# MSS_MIBSPIA register map
Vendor: Texas Instruments
Registers are 32-bit, access per field, no defined reset value unless marked. A register's access mark holds for its fields unless they carry their own. Offsets are as the file gives them; [hi:lo] are bit positions; lines under a group give offsets from that group; {n}, {i} and the like mark numbered series.

## MSS_MIBSPIA (part 3 of 4)
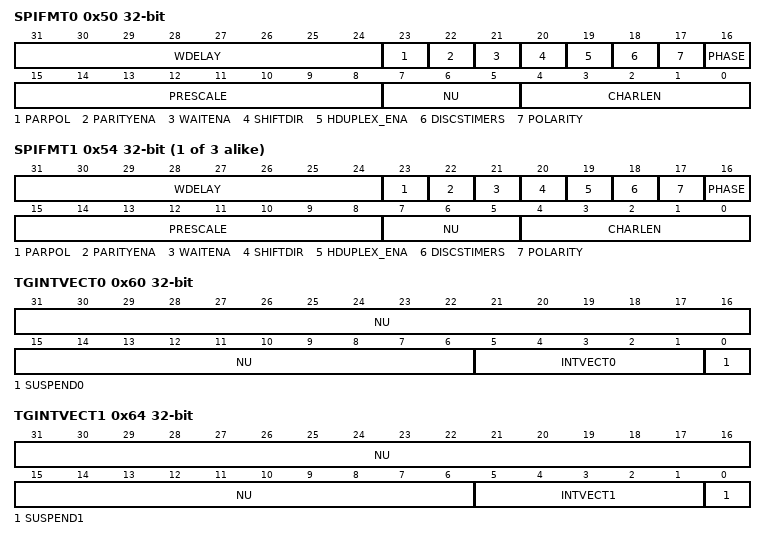
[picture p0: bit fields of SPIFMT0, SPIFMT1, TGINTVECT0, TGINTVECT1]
0x50 SPIFMT0 — SPI / MibSPI Data Format Register 0
  [31:24] WDELAY rw — Delay in between transmissions for data format x (x= 0,1,2,3). Idle time that will be applied at the end of the current transmission if the bit WDEL is set in the current buffer. The delay to be applied is equal to: WDELAY * PVBUSPCLK + 2 * PVBUSPCLK. PVBUSPCLK -> Period of VBUSPCLK.
  [23] PARPOL rw — Parity polarity: even or odd. PARPOLx can be modified in privilege mode only. It can be used for data format x (x= 0,1,2,3). 1 =An odd parity flag is added at the end of the transmit data stream. 0 =An even parity flag is added at the end of the transmit data stream.
  [22] PARITYENA rw — Parity enable for data format x. 1= A parity is transmitted at the end of each transmit data stream. At the end of a transfer the parity generator compares the received parity bit with the locally calculated parity flag. If the parity bits do not match the RXERR flag is set in the corresponding control field. The parity type (even or odd) can be selected via the PARPOL bit. 0= No parity generation/ verification is performed for this data format. If an Uncorrectable Error Flag is set in a Slave mode MibSPI, then wrong parity bit will be transmitted to indicate to the master that there has been some issue with the data parity. The SOMI pin will be forced to transmit all ‘0’s. And parity bit will be transmitted as ‘1’ if even parity is selected and as ‘0’ if odd parity is selected(using the PARPOLx bit of this register). This behavior will be irrespective of an UPE on either TXRAM or RXRAM.
  [21] WAITENA rw — Master waits for ENA signal from slave for data format x. WAITENA is considered in master mode only. In slave mode this bit has no meaning. WAITENA enables a flexible SPI network where slaves with ENA signal and slaves without ENA signal can be mixed. WAITENA defines for each buffer whether the addressed slave generates the ENA signal or does not. 1= Before the SPI / MibSPI starts the data transfer it waits for the ENA signal to become low. If the ENA signal is not pulled down by the addressed slave before the internal time-out counter (C2EDELAY) overflows, then the Master aborts the transfer and sets the TIMEOUT error flag. 0= The SPI / MibSPI does not wait for the ENA signal from the slaves and directly starts the transfer.
  [20] SHIFTDIR rw — Shift direction for data format x. With bit SHIFTDIRx the shift direction for data format x (x=0,1,2,3) can be selected. 1 =Data format x shift direction: Least significant bit is shifted out first. 0 =Data format x shift direction: Most significant bit is shifted out first.
  [19] HDUPLEX_ENA rw — Half Duplex transfer mode enable for Data Format x. This bit controls the I/O function of SOMI/SIMO lines for a specific requirement where in the case of Master mode, TX pin - SIMO will act as an RX pin, and in the case of Slave mode, RX pin - SIMO will act as a TX pin. 0 = Normal Full Duplex transfer. 1 = If MASTER = ‘1’, SIMO pin will act as an RX pin (No TX possible) If MASTER = ‘0’, SIMO pin will act as a TX pin (No RX possible). For all normal operations, HDUPLEX_ENAx bits should always remain ‘0’. It is intended for the usage when the SIMO pin is used for both TX & RX operations at different times.
  [18] DISCSTIMERS rw — Disable Chipselect Timers for this format register. The C2TDELAY & T2CDELAY timers are by default enabled for all the Data Format registers. Using this bit, these timers can be disabled for particular Data Format if not required. When a Master is handling multiple Slaves, with varied set-up hold requirement, the application can selectively choose to include or not include the ChipSelect Delay timers for any Slaves. 0 = Both C2TDELAY & T2CDELAY counts are inserted for the ChipSelects. 1 = No C2TDELAY or T2CDELAY is inserted in the ChipSelect timings.
  [17] POLARITY rw — SPI data format x clock polarity. POLARITYx defines the clock polarity of data format x. POLARITYx can be modified in privilege mode only. 1 =If POLARITYx is set to “1” the SPI clock signal is high-inactive, i.e. before and after data transfer the clock signal is high. 0 =If POLARITYx is set to “0” the SPI clock signal is low-inactive, i.e. before and after data transfer the clock signal is low.
  [16] PHASE rw — SPI Data format x clock delay. PHASEx defines the clock delay of data format x. PHASEx can be modified in privilege mode only. 1 =If PHASEx is set to “1” the SPI clock signal is delayed by a half SPI clock cycle versus the transmit / receive data stream. The first transmit bit has to output prior to the first clock edge. Master and slave receive the first bit with the first edge 0 =If PHASEx is set to “0” the SPI clock signal is not delayed versus the transmit / receive data stream. The first data bit is transmitted with the first clock edge and the first bit is received with the second (inverse) clock edge Note: Restriction on SPICLK Phase/Polarity change in Slave Mode In Slave mode if Phase and/or Polarity of SPICLK has to be changed, the following sequence should be used. oClear the GCR1.SPIEN bit to ‘0’. oSet the required Phase/Polarity values in SPIFMTx registers. oSet the GCR1.SPIEN bit back to ‘1’. The setting of GCR1.SPIEN bit in Slave SPI/MibSPI to ‘1’ should be done only after the Polarity of the incoming SPICLK signal changes (if POLARITYx bit was changed in the configuration).
  [15:8] PRESCALE rw — SPI data format x prescaler. PRESCALEx can be modified in privilege mode only. PRESCALEx determines the bit transfer rate of data format x if the SPI is the network master. PRESCALEx is directly derived from VBUSPCLK. If the SPI / MibSPI is configured as slave, PRESCALEx DOES NOT NEED to be configured. The clock rate for data format x can be calculated as BRFormat = VBUSPCLCK/(PRESCALEx+1) When PRESCALEx is set to zero (0), the SPI clock rate defaults to VBUSPCLK/2. Any write to this field will update EPRESCALE_FMTx field of EPRESCALEy (y=1,2) registers with EPRESCALE_FMTx(11:8) bits rounded off to ‘000’. Any write to EPRESCALE_FMTx field of the EXTENDED_PRESCALEy (y=1,2) register will cause its lower 8bits to be reflected in this field as well.
  [7:5] NU ro — Reserved. Reads return ‘0’ and writes have no effect.
  [4:0] CHARLEN rw — SPI data format x data word length. CHARLENx defines the word length of data format x. Legal values are 0x02 (data word length = 2 bit) to 0x10 (data word length = 16). Illegal values, such as 0x00 or 0x1F are not detected and their effect is indeterminate.
{0x50+4i} SPIFMT{i} (i=1..3) — SPI / MibSPI Data Format Register {i}
  [31:24] WDELAY rw
  [23] PARPOL rw
  [22] PARITYENA rw
  [21] WAITENA rw
  [20] SHIFTDIR rw
  [19] HDUPLEX_ENA rw
  [18] DISCSTIMERS rw
  [17] POLARITY rw
  [16] PHASE rw
  [15:8] PRESCALE rw
  [7:5] NU ro — Reserved. Reads return ‘0’ and writes have no effect.
  [4:0] CHARLEN rw
0x60 TGINTVECT0 ro — SPI Interrupt Vector Register 0 / MibSPI Transfer Group Interrupt Vector Register 0
  [31:6] NU — Reserved. Reads return ‘0’ and writes have no effect.
  [5:1] INTVECT0 — Interrupt vector for interrupt line INT0. INTVECT0 returns the vector of the pending interrupt at interrupt line INT0. If more than one interrupts are pending, INTVECT0 always references the highest priority interrupt source first. The vectors generated are different for SPI / Compatibility mode of MibSPI and Multibuffer mode of MibSPI. INTVECT0 field just reflects the status of SPIFLG register in a vectorized format. So, any updates to SPIFLG will automatically reflect in the Vector value in this register. SPI / Compatibility mode - MibSPI The interrupts available for SPI or Compatibility mode - MibSPI, in the descending order of their priorities are as given below. Transmission Error Interrupt Receive Buffer Overrun Interrupt Receive Buffer Full Interrupt Transmit Buffer Empty Interrupt Vectors for each of these interrupts will be reflected on the INTVECT0 bits, when they occur. Reading the vectors for the “Receive Buffer Overrun” & “Receive Buffer Full” interrupts will automatically clear the respective flags in the SPIFLG register. On reading the INTVECT0 bits, the vector of the next highest priority interrupt (if any) will be then reflected on the INTVECT0 bits. If two or more interrupts occur simultaneously, the vector for the higest priority interrupt will be reflected on the INTVECT0 bits. Reading the Vector register when “Transmitter Empty” is indicated does not clear the TXINTFLG in SPIFLG register. Writing a new data to SPIDATx register clears the “Transmitter Empty” interrupt. INTVECT0[4:0] Description 00000b no interrupt pending 10001b Error interrupt pending. Refer to Least Significant (LS) Byte of SPIFLG to determine more details about the type of error. 10011b Pending interrupt is “Receive Buffer Overrun Interrupt” 10010b Pending interrupt is “Receive Buffer Full Interrupt” 10100b Pending interrupt is “Transmit Buffer Empty Interrupt” All other bit combinations Reserved Note: Exception for clearing of RXINT If both SPIBUF and RXBUF (internal buffer) are full, then, reading TGINTVECT0 register (while it shows 10010) does not clear the RXINTFLG in SPIFLG register. In this case, only way to clear the Interrupt is to read the SPIBUF again until there’s no more unread RX data.
  [0] SUSPEND0 — “Transfer suspended” or “transfer finished” interrupt.(MibSPI only) The SUSPEND0 flag is updated depending on the type of interrupt reflected by the VECTOR value field. 1 =The interrupt type is a “transfer suspended” interrupt. I.e. the transfer group referenced by INTVECT0 has asserted an interrupt, because the buffer to be transferred next is in “suspend to wait” mode. 0 =The interrupt type is a “transfer finished” interrupt. I.e. the buffer array referenced by INTVECT0 has asserted an interrupt, because all of the data from the whole transfer group has been transferred. Note: Special case for SUSPEND interrupt When there’s a “transfer suspended” interrupt (SUSPEND0 bit is set to ‘1’), reading the TGINTVECT0 register does not clear the “TG Suspended” interrupt. The SUSPEND condition should be resolved first before the interrupt can be cleared. The SUSPEND condition can be cleared by writing a new data to that TXRAM location and/or reading the data from that RXRAM location depending upon the SUSPEND criteria programmed in the “BUFMODE” field of that TXRAM location. The SUSPEND0 bit always returns value ‘0’ in SPI / Compatibility mode MibSPI. When there is an RXOVRN or any Error interrupt in Multibuffer mode, SUSPEND0 bit stays ‘0’. Refer to Section 6.2 on page 77 & Section 6.3 on page 77 for more details and notes on better handling of interrupts. Note: Reading Error Vector Reading an Error Vector in the TGINTVECT0 register will NOT clear the Error flags in the SPIFLG register. The Error Flags in SPIFLG need to be write-cleared after servicing them suitably. If “TG Completed” interrupt occurs for a TG and after a while “TG Suspended” flag too gets set for the same TG, then the TGINTVECT0 register will show “TG Completed” interrupt giving it higher priority than the “TG Suspended” interrrupt.
0x64 TGINTVECT1 ro — SPI Interrupt Vector Register 1 / MibSPI Transfer Group Interrupt Vector Register 1
  [31:6] NU — Reserved. Reads return ‘0’ and writes have no effect.
  [5:1] INTVECT1 — Interrupt vector for interrupt line INT1. INTVECT1 returns the vector of the pending interrupt at interrupt line INT0. If more than one interrupt is pending, INTVECT1 always references the highest priority interrupt source first. The vectors generated are different for SPI / Compatibility mode of MibSPI and Multibuffer mode of MibSPI. INTVECT1 field just reflects the status of SPIFLG register in a vectorized format. So, any updates to SPIFLG will automatically reflect in the Vector value in this register. SPI / Compatibility mode - MibSPI The interrupts available for SPI / Compatibility mode - MibSPI, in the descending order of their priorities are as given below. Transmission Error Interrupt Receive Buffer Overrun Interrupt Receive Buffer Full Interrupt Transmit Buffer Empty Interrupt Vectors for each of these interrupts will be reflected on the INTVECT1 bits, when they occur. Reading the vectors for the “Receive Buffer Overrun” & “Receive Buffer Full” interrupts will automatically clear the respective flags in the SPIFLG register. On reading the INTVECT1 bits, the vector of the next highest priority interrupt (if any) will then be reflected on the INTVECT1 bits. If two or more interrupts occur simultaneously, the vector for the higest priority interrupt will be reflected on the INTVECT1 bits. Reading the Vector register when “Transmitter Empty” is indicated does not clear the TXINTFLG in SPIFLG register. Writing a new data to SPIDATx register clears the “Transmitter Empty” interrupt. 00000b no interrupt pending 10001b Error interrupt pending. Refer to LS Byte of SPIFLG to determine more details about the type of error. 10011b Pending interrupt is “Receive Buffer Overrun Interrupt” 10010b Pending interrupt is “Receive Buiffer Full Interrupt” 10100b Pending interrupt is “Transmit Buffer Empty Interrupt” All other bit combinations Reserved Note: Exception for clearing of RXINT If both SPIBUF and RXBUF (internal buffer) are full, then, reading TGINTVECT1 register (while it shows 10010) does not clear the RXINTFLG in SPIFLG register. In this case, only way to clear the Interrupt is to read out the SPIBUF again until there’s no more unread RX data.
  [0] SUSPEND1 — “Transfer suspended” or “transfer finished” interrupt.(MibSPI Only) The SUSPEND1 flag is updated depending on the type of interrupt reflected by the VECTOR value field. 1 =The interrupt type is a “transfer suspended” interrupt. I.e. the transfer group referenced by INTVECT1 has asserted an interrupt, because the buffer to be transferred next is in “suspend to wait” mode. 0 =The interrupt type is a “transfer finished” interrupt. I.e. the buffer array referenced by INTVECT1 has asserted an interrupt, because all data from the whole transfer group has been transferred. Note: Special case for SUSPEND interrupt When there’s a “transfer suspended” interrupt(SUSPEND1 bit is set to ‘1’), reading the TGINTVECT1 register does not clear the “TG Suspended” interrupt. The SUSPEND condition should be resolved first before the interrupt can be cleared. This condition can be cleared by writing a new data to that TXRAM location and/or reading the data from that RXRAM location depending upon the SUSPEND criteria programmed in the “BUFMODE” field of that TXRAM location. The SUSPEND1 bit always returns value ‘0’ in SPI / Compatibility mode MibSPI. Even while there is an RXOVRN or any Error interrupt in Multibuffer mode, SUSPEND1 bit stays ‘0’. Refer to Section 6.2 on page 77 & Section 6.3 on page 77 for more details and notes on better handling of interrupts. Note: Reading Error Vector Reading an Error Vector in the TGINTVECT1 register will NOT clear the Error flags in the SPIFLG register. The Error Flags in SPIFLG need to be write-cleared after servicing them suitably. If “TG Completed” interrupt occurs for a TG and after a while “TG Suspended” flag too gets set for the same TG, then the TGINTVECT1 register will show “TG Completed” interrupt giving it higher priority than the “TG Suspended” interrrupt.
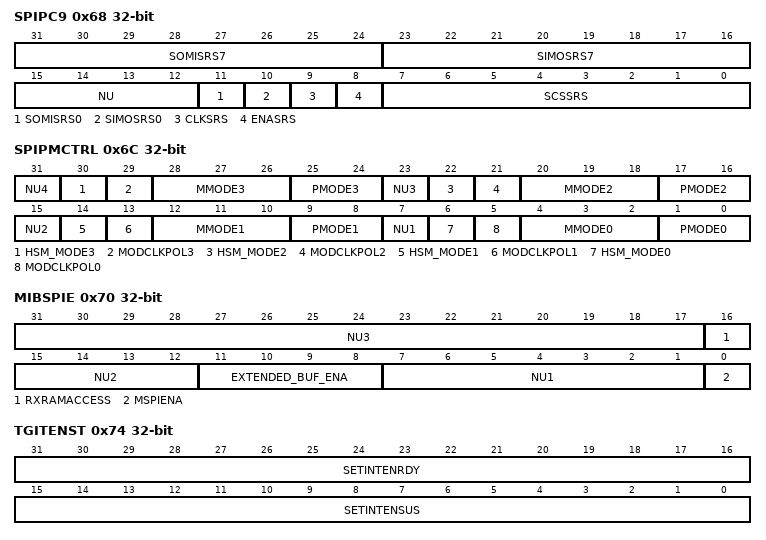
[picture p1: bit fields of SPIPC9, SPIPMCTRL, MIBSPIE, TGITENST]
0x68 SPIPC9 — SPI/MibSPI Pin Control Register 9 (SPIPC9) - SPISRSEL
  [31:24] SOMISRS7 rw — Each of these 7 bits controls the slew rate for the corresponding SPISOMIx pin. 0 =Normal Buffer Select. 1 =Slow Buffer Select.
  [23:16] SIMOSRS7 rw — Each of these 7 bits controls the slew rate for the corresponding SPISIMOx pin. 0 =Normal Buffer Select. 1 =Slow Buffer Select.
  [15:12] NU ro — Reserved. Reads return ‘0’ and writes have no effect.
  [11] SOMISRS0 rw — This bit controls the slew rate for SPISOMI0 pin. 0 =Normal Buffer Select. 1 =Slow Buffer Select. Note: Bit 11 or bit 24 can be used to control the slew rate for SPISOMI0. If a 32 bit write is performed, bit 11 will have priority over bit 24.
  [10] SIMOSRS0 rw — This bit controls the slew rate for SPISIMO0 pin. 0 =Normal Buffer Select. 1 =Slow Buffer Select. Note: Bit 10 or bit 16 can be used to control the slew rate for SPISIMO0. If a 32 bit write is performed, bit 10 will have priority over bit 16.
  [9] CLKSRS rw — This bit controls the slew rate for SPICLK pin. 0 =Normal Buffer Select. 1 =Slow Buffer Select.
  [8] ENASRS rw — This bit controls the slew rate for SPIENA pin. 0 =Fast Buffer Select. 1 =Slow Buffer Select.
  [7:0] SCSSRS rw — Each of these 7 bits controls the slew rate for the corresponding SPISCSx pin. 0 =Normal Buffer Select. 1 =Slow Buffer Select. Note: Effect of NUM_CS_PINS generic on ChipSelect bits. Actual number of bits implemented in SCSSRS[7:0] will depend upon the NUM_CS_PINS generic set during synthesis. Unimplemented bits will be read-only and will read ‘0’ always.
0x6C SPIPMCTRL — SPI/MibSPI Parallel/Modulo Mode Control Register
  [8n-1] NU{n} ro (n=1..4) — Reserved. Reads return ‘0’ and writes have no effect.
  [30] HSM_MODE3 rw — High Speed Modulo Mode control bit for Data Format 3. Controls whether the PMODE3 bits will result in Modulo Format data transfer or not. Refer to Section 3.26 for details about the HSM Mode. 0 = Normal mode - Normal Parallel mode if PMODE3 bits are non-zero. 1 = High Speed Modulo Mode. Data transfer will happen in Modulo Format if PMODE3 bits are non-zero
  [29] MODCLKPOL3 rw — Modulo mode SPICLK Polarity for Data Format 3 Determines the Polarity of the SPICLK in Modulo mode only. If MODULO MODE[2:0] bits are “000”, this bit will be ignored. 0 = Normal SPICLK in all the modes. 1 = Polarity of the SPICLK will be inverted if Modulo mode is selected
  [28:26] MMODE3 rw — These bits determine whether the SPI/MibSPI operates with 1, 2, 4, 5, or 6 data lines (if Modulo Option is supported by the module) for Data Format 3.000 = Normal single dataline mode - Default (PMODE should be set to “00”) 001 = 2-data line Mode (PMODE should be set to “00”) 010 = 3-data line mode (PMODE should be set to “00”) 011 = 4-data line mode (PMODE should be set to “00”) 100 = 5-data line mode (PMODE should be set to “00”) 101 = 6-data line mode (PMODE should be set to “01”) 110 = Reserved 111 = Reserved
  [25:24] PMODE3 rw — Parallel mode bits determine whether the SPI/MibSPI operates with 1, 2 ,4 or 8 data lines for Data Format 3. 00 = normal operation / 1-data line (MMODE should be set to “000”) 01 = 2-data line mode (MMODE should be set to “000”) 10 = 4-data line mode (MMODE should be set to “000”) 11 = 8-data line mode (MMODE should be set to “000”)
  [22] HSM_MODE2 rw — High Speed Modulo Mode control bit for Data Format 2. Controls whether the PMODE2 bits will result in Modulo Format data transfer or not. Refer to Section 3.26 for details about the HSM Mode. 0 = Normal mode - Normal Parallel mode if PMODE2 bits are non-zero. 1 = High Speed Modulo Mode. Data transfer will happen in Modulo Format if PMODE2 bits are non-zero
  [21] MODCLKPOL2 rw — Modulo mode SPICLK Polarity for Data Format 2. Determines the Polarity of the SPICLK in Modulo mode only. If MMODE[2:0] bits are “000”, this bit will be ignored. 0 = Normal SPICLK in all the modes. 1 = Polarity of the SPICLK will be inverted if Modulo mode is selected
  [20:18] MMODE2 rw — These bits determine whether the SPI/MibSPI operates with 1, 2, 4, 5, or 6 data lines (if Modulo Option is supported by the module) for Data Format 2. 000 = 1-data line Mode - Default (PMODE should be set to “00”) 001 = 2-data line Mode (PMODE should be set to “00”) 010 = 3-data line mode (PMODE should be set to “00”) 011 = 4-data line mode (PMODE should be set to “00”) 100 = 5-data line mode (PMODE should be set to “00”) 101 = 6-data line mode (PMODE should be set to “01”) 110 = Reserved 111 = Reserved
  [17:16] PMODE2 rw — Parallel mode bits determine whether the SPI/MibSPI operates with 1, 2 ,4 or 8 data lines for Data Format 2. 00 = normal operation / 1-data line (MMODE should be set to “000”) 01 = 2-data line mode (MMODE should be set to “000”)10 = 4-data line mode (MMODE should be set to “000”) 11 = 8-data line mode (MMODE should be set to “000”)
  [14] HSM_MODE1 rw — High Speed Modulo Mode control bit for Data Format 1. Controls whether the PMODE1 bits will result in Modulo Format data transfer or not. Refer to Section 3.26 for details about the HSM Mode. 0 = Normal mode - Normal Parallel mode if PMODE1 bits are non-zero. 1 = High Speed Modulo Mode. Data transfer will happen in Modulo Format if PMODE1 bits are non-zero.
  [13] MODCLKPOL1 rw — Modulo mode SPICLK Polarity for Data Format 1. Determines the Polarity of the SPICLK in Modulo mode only. If MMODE[2:0] bits are “000”, this bit will be ignored. 0 = Normal SPICLK in all the modes. 1 = Polarity of the SPICLK will be inverted if Modulo mode is selected.
  [12:10] MMODE1 rw — These bits determine whether the SPI/MibSPI operates with 1, 2, 4, 5, or 6 data lines (if Modulo Option is supported by the module) for Data Format 1. 000 = 1-data line Mode - Default (PMODE should be set to “00”) 001 = 2-data line Mode (PMODE should be set to “00”) 010 = 3-data line mode (PMODE should be set to “00”) 011 = 4-data line mode (PMODE should be set to “00”) 100 = 5-data line mode (PMODE should be set to “00”) 101 = 6-data line mode (PMODE should be set to “01”) 110 = Reserved 111 = Reserved
  [9:8] PMODE1 rw — Parallel mode bits determine whether the SPI/MibSPI operates with 1, 2 ,4 or 8 data lines for Data Format 1. 00 = normal operation / 1-data line (MMODE should be set to “000”) 01 = 2-data line mode (MMODE should be set to “000”) 10 = 4-data line mode (MMODE should be set to “000”) 11 = 8-data line mode (MMODE should be set to “000”)
  [6] HSM_MODE0 rw — High Speed Modulo Mode control bit for Data Format 0. Controls whether the PMODE0 bits will result in Modulo Format data transfer or not. Refer to Section 3.26 for details about the HSM Mode. 0 = Normal mode - Normal Parallel mode if PMODE0 bits are non-zero. 1 = High Speed Modulo Mode. Data transfer will happen in Modulo Format if PMODE0 bits are non-zero.
  [5] MODCLKPOL0 rw — Modulo mode SPICLK Polarity for Data Format 0. Determines the Polarity of the SPICLK in Modulo mode only. If MMODE[2:0] bits are “000”, this bit will be ignored. 0 = Normal SPICLK in all the modes. 1 = Polarity of the SPICLK will be inverted if Modulo mode is selected.
  [4:2] MMODE0 rw — These bits determine whether the SPI/MibSPI operates with 1, 2, 4, 5, or 6 data lines (if Modulo Option is supported by the module) for Data Format 0. 000 = 1-data line Mode - Default (PMODE should be set to “00”) 001 = 2-data line Mode (PMODE should be set to “00”) 010 = 3-data line mode (PMODE should be set to “00”) 011 = 4-data line mode (PMODE should be set to “00”) 100 = 5-data line mode (PMODE should be set to “00”) 101 = 6-data line mode (PMODE should be set to “01”) 110 = Reserved 111 = Reserved
  [1:0] PMODE0 rw — Parallel mode bits determine whether the SPI/MibSPI operates with 1, 2 ,4 or 8 data lines for Data Format 0. 00 = normal operation / 1-data line (MMODE should be set to “000”) 01 = 2-data line mode (MMODE should be set to “000”) 10 = 4-data line mode (MMODE should be set to “000”) 11 = 8-data line mode (MMODE should be set to “000”)
0x70 MIBSPIE — MibSPI Enable Register
  [31:17] NU3 ro — Reserved. Reads return ‘0’ and writes have no effect.
  [16] RXRAMACCESS rw — Receive RAM Access control Bit. During normal operating mode of MibSPI, the Receive Data/Status portion of Multibuffer RAM is read-only. To enable testing of Data Integrity checks of Receive RAM, a special read/write access control is provided through this bit. 0 = The RX portion of Multibuffer RAM is not writable by the CPU. That is, portion of Multibuffer RAM, addressed by an offset of 0x200-0x3FF is write protected. 1 = The whole of Multibuffer RAM is fully accessible for read/write by the CPU.
  [15:12] NU2 ro — Reserved.Reads return ‘0’ and writes have no effect
  [11:8] EXTENDED_BUF_ENA rw — Enables the support for 256 buffers. By default MibSPI supports up to 128 buffers for both TX and RX. It is also possible to extend the support to 256 buffers as a parameterized implementation. This field can be used to enable/disable the support for Extended Buffers. This Enable field is implemented only if “EXTENDED_BUF” parameter is set to ‘1’. If the parameter is set to ‘0’, this field is read-only and reads the disable value. Write (Privilege mode only) 1010 - Enable the Extended Buffer mode - up to 256 buffers can be used 0101 - Disable the Extended Buffer mode - MibSPI supports only 128 buffers All other values - writes are ignored and the values are not updated into this field. The state of the feature remains unchanged. Read (both privilege and user modes) 1010 - Extended Buffer mode is enabled - up to 256 buffers can be used 0101 - Extended Buffer mode is disabled - MibSPI supports only 128 buffers
  [7:1] NU1 ro — Reserved. Reads return ‘0’ and writes have no effect.
  [0] MSPIENA rw — Multibuffer mode Enable. After power-up or reset MSPIENA remains cleared, which means that the MibSPI runs in compatibility mode by default. If Multibuffer mode is desired, this register should be configured first after configuring the SPIGCR0 register. Unless MSPIENA is set to ‘1’, the Multibuffer mode registers are not writable. Refer to Section 3.3 for the grouping of registers into Compatibility mode and Multibuffer mode. 1 =The MibSPI is configured to run in MibSPI mode (Multibuffer mode). In this mode the additional features are available. 0 =The MibSPI runs in compatibility mode, i.e. in this mode the MibSPI is fully code compliant to the standard TMS470 Platform SPI. No Multibuffer feature is supported
0x74 TGITENST rw — MibSPI Transfer Group Interrupt Enable Set Register
  [31:16] SETINTENRDY — Transfer group interrupt set (enable) when transfer finished. Write: 1 = Enables the “The Transfer group x completed “ interrupt Interrupt gets generated when Transfer Group x gets completed. 0 = Has no effect. Read: 1 = “The Transfer group x completed “ interrupt is enabled Interrupt gets generated when Transfer Group x gets completed. 0 = “The Transfer group x completed” interrupt is disabled Interrupt does not get generated when Transfer Group x gets completed
  [15:0] SETINTENSUS — Transfer group interrupt set (enable) when transfer suspended Write: 1 = Enables the “The Transfer group x suspended “ interrupt Interrupt gets generated when Transfer Group x gets suspended. 0 = Has no effect. Read: 1 = “The Transfer group x suspended “ interrupt is enabled Interrupt gets generated when Transfer Group x gets suspended. 0 = “The Transfer group x suspended” interrupt is disabled Interrupt does not get generated when Transfer Group x gets suspended
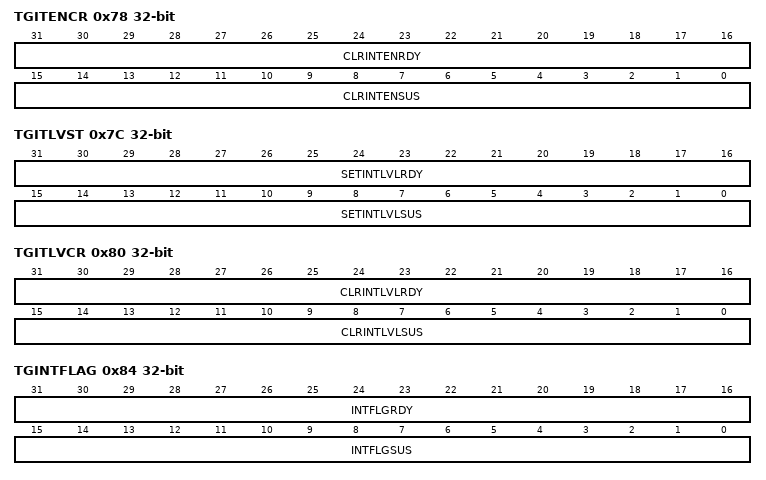
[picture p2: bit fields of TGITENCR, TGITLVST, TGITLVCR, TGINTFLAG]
0x78 TGITENCR rw — MibSPI Transfer Group Interrupt Enable Clear Register
  [31:16] CLRINTENRDY — Transfer group interrupt clear (disable) when transfer finished. Write: 1 = Disables the “The Transfer group x completed “ interrupt Interrupt does not get generated when Transfer Group x gets completed. 0 = Has no effect. Read: 1 = “The Transfer group x completed “ interrupt is enabled Interrupt gets generated when Transfer Group x gets completed. 0 = “The Transfer group x completed” interrupt is disabled Interrupt does not get generated when Transfer Group x gets completed
  [15:0] CLRINTENSUS — Transfer group interrupt clear (disable) when transfer suspended Write: 1 = Disables the “The Transfer group x suspended “ interrupt Interrupt does not get generated when Transfer Group x gets suspended. 0 = Has no effect. Read: 1 = “The Transfer group x suspended “ interrupt is enabled Interrupt gets generated when Transfer Group x gets suspended. 0 = “The Transfer group x suspended” interrupt is disabled Interrupt does not get generated when Transfer Group x gets suspended
0x7C TGITLVST rw — MibSPI Transfer Group Interrupt Level Set Register
  [31:16] SETINTLVLRDY — Transfer group completed” Interrupt Level set register Write: 1 = Sets the “The Transfer group x completed “ interrupt to line INT1 0 = Has no effect. Read: 1 = “The Transfer group x completed “ interrupt is set to line INT1 0 = “The Transfer group x completed “ interrupt is set to line INT0
  [15:0] SETINTLVLSUS — Transfer group suspended” interrupt Level set rigester Write: 1 = Sets the “The Transfer group x suspended “ interrupt to line INT1 0 = Has no effect. Read: 1 = “The Transfer group x suspended “ interrupt is set to line INT1 0 = “The Transfer group x suspended “ interrupt is set to line INT0
0x80 TGITLVCR rw — MibSPI Transfer Group Interrupt Level Clear Register
  [31:16] CLRINTLVLRDY — Transfer group completed” Interrupt Level clear register Write: 1 = Sets the “The Transfer group x completed “ interrupt to line INT0 0 = Has no effect. Read: 1 = “The Transfer group x completed “ interrupt is set to line INT1 0 = “The Transfer group x completed “ interrupt is set to line INT0
  [15:0] CLRINTLVLSUS — Transfer group suspended” interrupt Level clear register Write: 1 = Sets the “The Transfer group x suspended “ interrupt to line INT0 0 = Has no effect. Read: 1 = “The Transfer group x suspended “ interrupt is set to line INT1 0 = “The Transfer group x suspended “ interrupt is set to line INT0
0x84 TGINTFLAG ro — Transfer Group Interrupt Flag Register
  [31:16] INTFLGRDY — Transfer group interrupt flag for “transfer finished” interrupt. Read: 1 =A “transfer finished” interrupt from transfer group x occurred. No matter whether the interrupt is enabled or disabled (INTENRDYx = don’t care) or whether the interrupt is mapped to line INT0 or INT1, INTFLGRDYx is set right after the transfer from transfer group x is finished. 0 =No “transfer finished” interrupt occurred since last clearing of the flag INTFLGRDYx. Write: 1 = Clears the corresponding bit flag. 0 = Has no effect.
  [15:0] INTFLGSUS — Transfer group interrupt flag for “transfer suspend” interrupt. Read: 1 =A “transfer suspended” interrupt from transfer group x occurred. No matter whether the interrupt is enabled or disabled (INTENSUSx = don’t care) or whether the interrupt is mapped to line INT0 or INT1, INTFLGSUSx is set right after the transfer from transfer group x is suspended. 0 =No ”transfer suspended” interrupt occurred since last clearing of the flag INTFLGSUSx. Note: Read Clear Behavior Reading the interrupt vector registers TGINTVECT0 or TGINTVECT1 automatically clears the interrupt flag bit INTFLGRDYx referenced by the vector number given by INTVECT0/INTVECT1 bits, if SUSPEND0/SUPEND1 bit in the Vector registers is ‘0’.
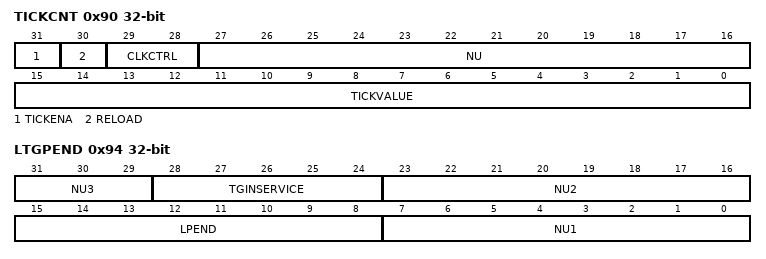
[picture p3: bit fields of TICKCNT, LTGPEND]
0x90 TICKCNT — Tick Count Register
  [31] TICKENA rw — Tick counter enable. 1 =The MibSPI internal tick counter is enabled and is clocked by the clock source selected by CLKCTRL[1:0]. When the tick counter is enabled it starts down-counting from its current value. When TICKENA goes from “0” to “1” the tick counter is automatically loaded with the TICKVALUE. 0 =The MibSPI internal tick counter is disabled. The counter value remains unchanged. Note: When the tick counter is disabled the trigger signal is forced low.
  [30] RELOAD ro — Re-load tick counter. RELOAD is a set-only bit, i.e. writing a “1” to it automatically reloads the Tick Counter with the value stored in TICKVALUE. Reading RELOAD always returns a “0”. Note: When the tick counter is reloaded by the RELOAD bit, the trigger signal is not toggled.
  [29:28] CLKCTRL rw — Tick counter clock source control. CLKCTRL[1:0] defines the clock source that is used to clock the MibSPI internal tick counter.CLKCTRL[1:0] Description 00b SPICLK of Data word format 0 is selected as clock source of tick counter 01b SPICLK of Data word format 1 is selected as clock source of tick counter 10b SPICLK of Data word format 2 is selected as clock source of tick counter 11b SPICLK of Data word format 3 is selected as clock source of tick counter
  [27:16] NU ro — Reserved.Reads return ‘0’ and writes have no effect
  [15:0] TICKVALUE rw — Initial value for tick counter. TICKVALUE stores the initial value for the tick counter. The tick counter is loaded with TICKVALUE every time an under-flow condition occurs and every time the RELOAD flag is set by the host
0x94 LTGPEND — Last Transfer Group End Pointer
  [31:29] NU3 ro — Reserved.Reads return ‘0’ and writes have no effect
  [28:24] TGINSERVICE ro — Transfer Group currently being serviced by the Sequencer. Read-Only field indicating the current Transfer Group that is being serviced. This field can generally be used for code debug purpose. Read Value:TG IN SERVICE[4:0] Description 00000b No Transfer Group is being serviced by the Sequencer 00001b Transfer Group0 is being serviced by the Sequencer ... ... 10000b Transfer Group15 is being serviced by the Sequencer 10001b - 11111b Invalid values
  [23:16] NU2 ro — Reserved.Reads return ‘0’ and writes have no effect
  [15:8] LPEND rw — Last Transfer Group End Pointer Usually the transfer group end address (PEND) is inherently defined by the start value of the starting pointer of the subsequent transfer group (PSTART). The transfer group ends at the buffer one before the next transfer group starts (PEND[x]=PSTART[x+1] - 1). For a full configuration of MibSPI, the 15th transfer group has no subsequent transfer group, i.e. no end address is inherently defined. Therefore LPEND has to be programmed to specify explicitly the end address of the 15th transfer group. Number of Transfer Groups implemented in a MibSPI can vary from one MibSPI to another since it is a generic parameter based implementation. If in a MibSPI, only 4 Transfer Groups are implemented, then the PEND of the 4th TG is defined by LPEND values defined in this LTGPEND register.
  [7:0] NU1 ro — Reserved.Reads return ‘0’ and writes have no effect
